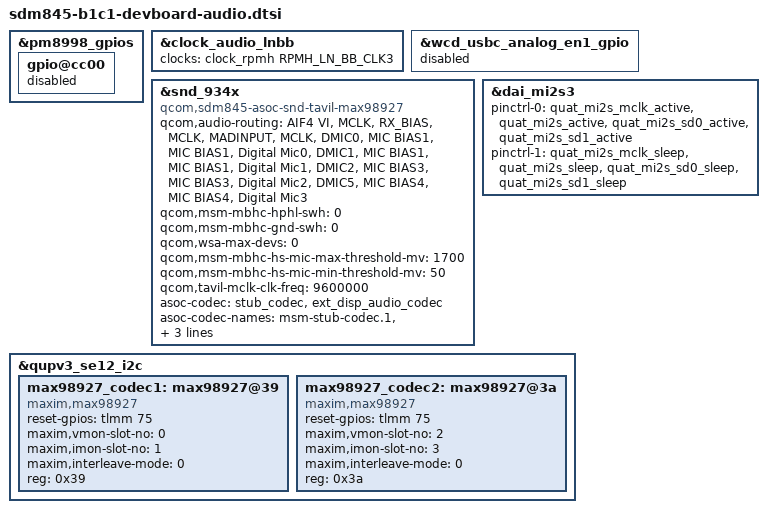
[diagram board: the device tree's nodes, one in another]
/* AUDIO: RESET: GPIO64, INTR1: GPIO54, INTR2: GPIO53, EXT_CLK: PM845.68
 * LN_BB_CLK3, SLIMBUS_CLK: GPIO70, SLIMBUS_DATA[0..1]: GPIO71,GPIO72 */

#include <dt-bindings/clock/qcom,audio-ext-clk.h>
#include "sdm845-audio-overlay.dtsi"

&pm8998_gpios {
	gpio@cc00 { /* GPIO 13 */
		status = "disabled";
	};
};

&clock_audio_lnbb {
	clocks = <&clock_rpmh RPMH_LN_BB_CLK3>;
};

&wcd_usbc_analog_en1_gpio {
	status = "disabled";
};

&snd_934x {
	compatible = "qcom,sdm845-asoc-snd-tavil-max98927";
	qcom,audio-routing =
		"AIF4 VI", "MCLK",
		"RX_BIAS", "MCLK",
		"MADINPUT", "MCLK",
		"DMIC0", "MIC BIAS1",
		"MIC BIAS1", "Digital Mic0",
		"DMIC1", "MIC BIAS1",
		"MIC BIAS1", "Digital Mic1",
		"DMIC2", "MIC BIAS3",
		"MIC BIAS3", "Digital Mic2",
		"DMIC5", "MIC BIAS4",
		"MIC BIAS4", "Digital Mic3";

	qcom,msm-mbhc-hphl-swh = <0>;
	qcom,msm-mbhc-gnd-swh = <0>;
	qcom,wsa-max-devs = <0>;
	qcom,msm-mbhc-hs-mic-max-threshold-mv = <1700>;
	qcom,msm-mbhc-hs-mic-min-threshold-mv = <50>;

	qcom,tavil-mclk-clk-freq = <9600000>;
	asoc-codec = <&stub_codec>, <&ext_disp_audio_codec>;
	asoc-codec-names = "msm-stub-codec.1",
			   "msm-ext-disp-audio-codec-rx";

	pinctrl-names = "aud_active", "aud_sleep";
	pinctrl-0 = <&wcd_usbc_analog_en2_active>;
	pinctrl-1 = <&wcd_usbc_analog_en2_idle>;
};

/* path to speaker boosters */
&dai_mi2s3 {
	/* AP in SD0 (gpio60), AP out SD1 (gpio61); */
	/* SD0; in; ("rx-lines" is playback path): mask=1 */
	/* SD1; out ("tx-lines" is capture path): mask=2 */
	pinctrl-names = "default", "sleep";
	pinctrl-0 =
	<&quat_mi2s_mclk_active &quat_mi2s_active &quat_mi2s_sd0_active
	&quat_mi2s_sd1_active>;
	pinctrl-1 =
	<&quat_mi2s_mclk_sleep &quat_mi2s_sleep &quat_mi2s_sd0_sleep
	&quat_mi2s_sd1_sleep>;
};

/* speaker boosters */
&qupv3_se12_i2c {
	status = "ok";
	max98927_codec1: max98927@39 {
		compatible = "maxim,max98927";
		reset-gpios = <&tlmm 75 0x00>;
		maxim,vmon-slot-no = <0>;
		maxim,imon-slot-no = <1>;
		maxim,interleave-mode = <0>;
		reg = <0x39>;
	};
	max98927_codec2: max98927@3a {
		compatible = "maxim,max98927";
		reset-gpios = <&tlmm 75 0x00>;
		maxim,vmon-slot-no = <2>;
		maxim,imon-slot-no = <3>;
		maxim,interleave-mode = <0>;
		reg = <0x3a>;
	};
};
